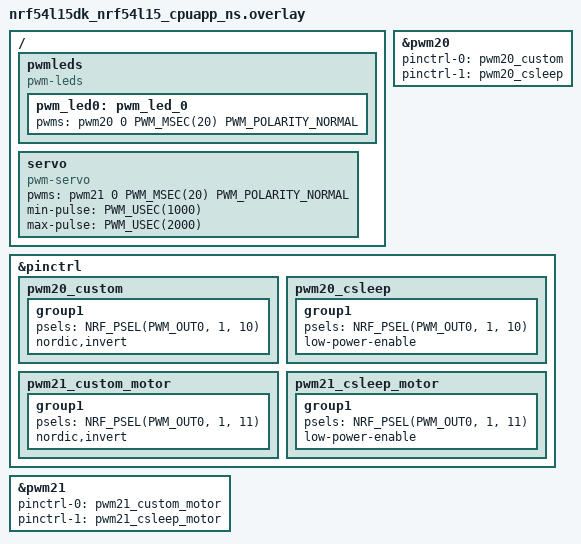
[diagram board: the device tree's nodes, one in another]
/* STEP 1.2 -  Add a pwm_led instance and change the polarity */
/{
    pwmleds {
        compatible = "pwm-leds";
        pwm_led0: pwm_led_0 {
            pwms = <&pwm20 0 PWM_MSEC(20) PWM_POLARITY_NORMAL>;
        };
    };
};

/* STEP 1.3 - Add your own custom pwm0 instance */
&pwm20 {
    status = "okay";
    pinctrl-0 = <&pwm20_custom>;
    pinctrl-1 = <&pwm20_csleep>;
    pinctrl-names = "default", "sleep";
};

/* STEP 1.4 - Configure which pins your custom pwm0 instance should use */
&pinctrl {
    pwm20_custom: pwm20_custom {
        group1 {
            psels = <NRF_PSEL(PWM_OUT0, 1, 10)>;
            nordic,invert;
        };
    };

    pwm20_csleep: pwm20_csleep {
        group1 {
            psels = <NRF_PSEL(PWM_OUT0, 1, 10)>;
            low-power-enable;
        };
    };
};

/* STEP 5.2 - Add the servo device  */
/ {
    servo: servo {
        compatible = "pwm-servo";
        pwms = <&pwm21 0 PWM_MSEC(20) PWM_POLARITY_NORMAL>;
        min-pulse = <PWM_USEC(1000)>;
        max-pulse = <PWM_USEC(2000)>;
    };
};

/* STEP 5.3 - Configure which pins pwm1 should use */
&pwm21 {
    status = "okay";
    pinctrl-0 = <&pwm21_custom_motor>;
    pinctrl-1 = <&pwm21_csleep_motor>;
    pinctrl-names = "default", "sleep";
};

&pinctrl {
    pwm21_custom_motor: pwm21_custom_motor {
        group1 {
            psels = <NRF_PSEL(PWM_OUT0, 1, 11)>;
            nordic,invert;
        };
    };

    pwm21_csleep_motor: pwm21_csleep_motor {
        group1 {
            psels = <NRF_PSEL(PWM_OUT0, 1, 11)>;
            low-power-enable;
        };
    };
};
